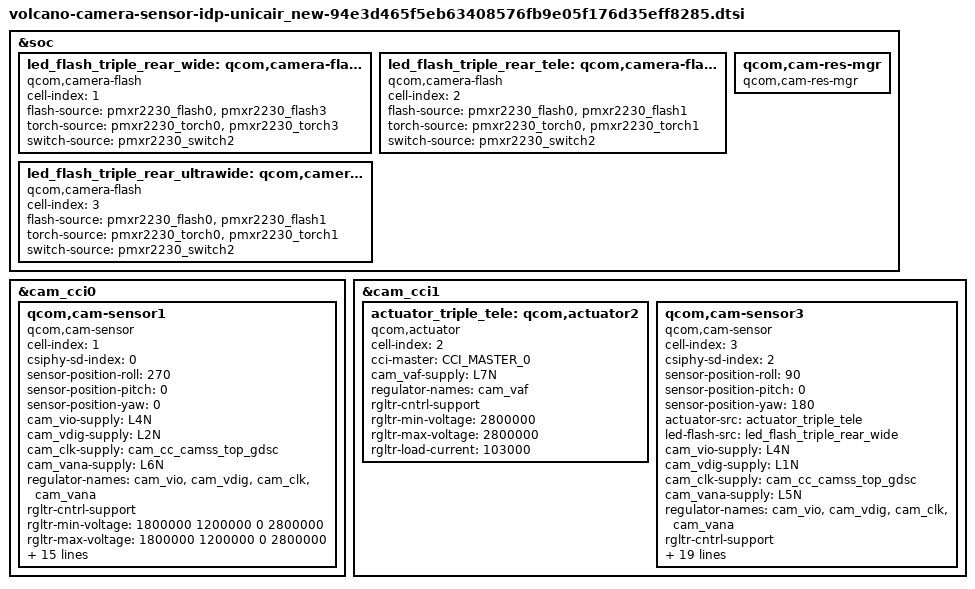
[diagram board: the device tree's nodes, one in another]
#include <dt-bindings/msm-camera.h>

&soc {
	led_flash_triple_rear_wide: qcom,camera-flash1 {
		cell-index = <1>;
		compatible = "qcom,camera-flash";
		flash-source = <&pmxr2230_flash0 &pmxr2230_flash3>;
		torch-source = <&pmxr2230_torch0 &pmxr2230_torch3>;
		switch-source = <&pmxr2230_switch2>;
		status = "ok";
	};

	led_flash_triple_rear_tele: qcom,camera-flash2 {
		cell-index = <2>;
		compatible = "qcom,camera-flash";
		flash-source = <&pmxr2230_flash0 &pmxr2230_flash1>;
		torch-source = <&pmxr2230_torch0 &pmxr2230_torch1>;
		switch-source = <&pmxr2230_switch2>;
		status = "ok";
	};

	led_flash_triple_rear_ultrawide: qcom,camera-flash3 {
		cell-index = <3>;
		compatible = "qcom,camera-flash";
		flash-source = <&pmxr2230_flash0 &pmxr2230_flash1>;
		torch-source = <&pmxr2230_torch0 &pmxr2230_torch1>;
		switch-source = <&pmxr2230_switch2>;
		status = "ok";
	};

	qcom,cam-res-mgr {
		compatible = "qcom,cam-res-mgr";
		status = "ok";
	};
};

&cam_cci0 {
	qcom,cam-sensor1 {
		cell-index = <1>;
		compatible = "qcom,cam-sensor";
		csiphy-sd-index = <0>;
		sensor-position-roll = <270>;
		sensor-position-pitch = <0>;
		sensor-position-yaw = <0>;
		cam_vio-supply = <&L4N>;
		cam_vdig-supply = <&L2N>;
		cam_clk-supply = <&cam_cc_camss_top_gdsc>;
		cam_vana-supply = <&L6N>;
		regulator-names = "cam_vio", "cam_vdig", "cam_clk",
			"cam_vana";
		rgltr-cntrl-support;
		rgltr-min-voltage = <1800000 1200000 0 2800000>;
		rgltr-max-voltage = <1800000 1200000 0 2800000>;
		rgltr-load-current = <1060 643640 0 82860>;
		gpio-no-mux = <0>;
		pinctrl-names = "cam_default", "cam_suspend";
		pinctrl-0 = <&cam_sensor_mclk0_active
				 &cam_sensor_active_rst0>;
		pinctrl-1 = <&cam_sensor_mclk0_suspend
				 &cam_sensor_suspend_rst0>;
		gpios = <&tlmm 83 0>,
			<&tlmm 95 0>;
		gpio-reset = <1>;
		gpio-req-tbl-num = <0 1>;
		gpio-req-tbl-flags = <1 0>;
		gpio-req-tbl-label = "CAMIF_MCLK0",
					"CAM_RESET0";
		cci-master = <CCI_MASTER_0>;
		clocks = <&camcc CAM_CC_MCLK0_CLK>;
		clock-names = "cam_clk";
		clock-cntl-level = "nominal";
		clock-rates = <24000000>;
		status = "ok";
	};

};

&cam_cci1 {
	actuator_triple_tele: qcom,actuator2{
		cell-index = <2>;
		compatible = "qcom,actuator";
		cci-master = <CCI_MASTER_0>;
		cam_vaf-supply = <&L7N>;
		regulator-names = "cam_vaf";
		rgltr-cntrl-support;
		rgltr-min-voltage = <2800000>;
		rgltr-max-voltage = <2800000>;
		rgltr-load-current = <103000>;
		status = "ok";
	};

	/*eeprom_tele: qcom,eeprom3 {
		cell-index = <3>;
		compatible = "qcom,eeprom";
		cam_vio-supply = <&L5N>;
		cam_vdig-supply = <&L2M>;
		cam_clk-supply = <&cam_cc_camss_top_gdsc>;
		cam_vana-supply = <&L4M>;
		cam_vaf-supply = <&L7M>;
		regulator-names = "cam_vio", "cam_vdig", "cam_clk",
			"cam_vana", "cam_vaf";
		rgltr-cntrl-support;
		rgltr-min-voltage = <1800000 1056000 0 2800000 2800000>;
		rgltr-max-voltage = <1800000 1056000 0 2800000 2800000>;
		rgltr-load-current = <10000 140000 0 52000 103000>;
		gpio-no-mux = <0>;
		pinctrl-names = "cam_default", "cam_suspend";
		pinctrl-0 = <&cam_sensor_mclk2_active
				 &cam_sensor_active_rst2>;
		pinctrl-1 = <&cam_sensor_mclk2_suspend
				 &cam_sensor_suspend_rst2>;
		gpios = <&tlmm 85 0>,
			<&tlmm 42 0>;
		gpio-reset = <1>;
		gpio-req-tbl-num = <0 1>;
		gpio-req-tbl-flags = <1 0>;
		gpio-req-tbl-label = "CAMIF_MCLK2",
					"CAM_RESET2";
		cci-master = <CCI_MASTER_0>;
		clocks = <&camcc CAM_CC_MCLK2_CLK>;
		clock-names = "cam_clk";
		clock-cntl-level = "nominal";
		clock-rates = <24000000>;
		status = "ok";
	};*/
	
	qcom,cam-sensor3 {
		cell-index = <3>;
		compatible = "qcom,cam-sensor";
		csiphy-sd-index = <2>;
		sensor-position-roll = <90>;
		sensor-position-pitch = <0>;
		sensor-position-yaw = <180>;
		//eeprom-src = <&eeprom_tele>;
		actuator-src = <&actuator_triple_tele>;
		led-flash-src = <&led_flash_triple_rear_wide>;
		cam_vio-supply = <&L4N>;
		cam_vdig-supply = <&L1N>;
		cam_clk-supply = <&cam_cc_camss_top_gdsc>;
		cam_vana-supply = <&L5N>;
		regulator-names = "cam_vio", "cam_vdig", "cam_clk",
			"cam_vana";
		rgltr-cntrl-support;
		rgltr-min-voltage = <1800000 1200000 0 2800000>;
		rgltr-max-voltage = <1800000 1200000 0 2800000>;
		rgltr-load-current = <10000 140000 0 52000>;
		gpio-no-mux = <0>;
		pinctrl-names = "cam_default", "cam_suspend";
		pinctrl-0 = <&cam_sensor_mclk1_active
				 &cam_sensor_active_rst2>;
		pinctrl-1 = <&cam_sensor_mclk1_suspend
				 &cam_sensor_suspend_rst2>;
		gpios = <&tlmm 84 0>,
			<&tlmm 94 0>,<&tlmm 166 0>;
		gpio-reset = <1>;
		gpio-standby = <2>;
		gpio-req-tbl-num = <0 1 2>;
		gpio-req-tbl-flags = <1 0 0>;
		gpio-req-tbl-label = "CAMIF_MCLK2",
					"CAM_RESET2","CAM_STANDBY2";
		cci-master = <CCI_MASTER_0>;
		clocks = <&camcc CAM_CC_MCLK1_CLK>;
		clock-names = "cam_clk";
		clock-cntl-level = "nominal";
		clock-rates = <24000000>;
		status = "ok";
	};

};
